# eusci_b register map
Vendor: Texas Instruments
Peripheral module from a debugger description file (folder MSP432).
Registers are 16-bit, read-write, no defined reset value unless marked. A register's access mark holds for its fields unless they carry their own. Offsets are as the file gives them; lines under a group give offsets from that group; [hi:lo] are bit positions; {n}, {i} and the like mark numbered series; 'fields as' and 'values as' point back to an identical list; <NAME> marks a mode.

## eUSCI_B
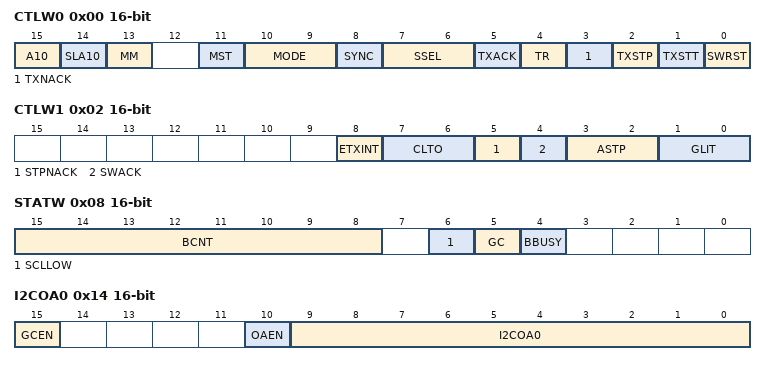
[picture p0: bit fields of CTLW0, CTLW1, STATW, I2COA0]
0x00 CTLW0 — eUSCI_Bx Control Word Register 0
  [15] A10 — Own addressing mode select. Modify only when UCSWRST = 1.
    0=A10__0 (Own address is a 7-bit address); 1=A10__1 (Own address is a 10-bit address)
  [14] SLA10 — Slave addressing mode select
    0=SLA10__0 (Address slave with 7-bit address); 1=SLA10__1 (Address slave with 10-bit address)
  [13] MM — Multi-master environment select. Modify only when UCSWRST = 1.
    0=MM__0 (Single master environment); 1=MM__1 (Multi-master environment)
  [11] MST — Master mode select
    0=MST__0 (Slave mode); 1=MST__1 (Master mode)
  [10:9] MODE — eUSCI_B mode
    0=MODE__0 (3-pin SPI); 1=MODE__1 (4-pin SPI (master or slave enabled if STE = 1)); 2=MODE__2 (4-pin SPI (master or slave enabled if STE = 0)); 3=MODE__3 (I2C mode)
  [8] SYNC — Synchronous mode enable. For eUSCI_B always read and write as 1.
    0=SYNC__0 (Asynchronous mode); 1=SYNC__1 (Synchronous mode)
  [7:6] SSEL — eUSCI_B clock source select
    0=SSEL__0 (UCLKI); 1=SSEL__1 (ACLK); 2=SSEL__2 (SMCLK); 3=SSEL__3 (SMCLK)
  [5] TXACK — Transmit ACK condition in slave mode with enabled address mask
    0=TXACK__0 (Do not acknowledge the slave address); 1=TXACK__1 (Acknowledge the slave address)
  [4] TR — Transmitter/receiver
    0=TR__0 (Receiver); 1=TR__1 (Transmitter)
  [3] TXNACK — Transmit a NACK
    0=TXNACK__0 (Acknowledge normally); 1=TXNACK__1 (Generate NACK)
  [2] TXSTP — Transmit STOP condition in master mode
    0=TXSTP__0 (No STOP generated); 1=TXSTP__1 (Generate STOP)
  [1] TXSTT — Transmit START condition in master mode
    0=TXSTT__0 (Do not generate START condition); 1=TXSTT__1 (Generate START condition)
  [0] SWRST — Software reset enable Modify only when UCSWRST = 1.
    0=SWRST__0 (Disabled. eUSCI_B reset released for operation); 1=SWRST__1 (Enabled. eUSCI_B logic held in reset state)
0x02 CTLW1 — eUSCI_Bx Control Word Register 1
  [8] ETXINT — Early UCTXIFG0
    0=ETXINT__0 (UCTXIFGx is set after an address match with UCxI2COAx and the d); 1=ETXINT__1 (UCTXIFG0 is set for each START condition)
  [7:6] CLTO — Clock low timeout select. Modify only when UCSWRST = 1.
    0=CLTO__0 (Disable clock low timeout counter); 1=CLTO__1 (135 000 SYSCLK cycles (approximately 28 ms)); 2=CLTO__2 (150 000 SYSCLK cycles (approximately 31 ms)); 3=CLTO__3 (165 000 SYSCLK cycles (approximately 34 ms))
  [5] STPNACK — The UCSTPNACK bit allows to make the eUSCI_B master acknowledge
    0=STPNACK__0 (Send a non-acknowledge before the STOP condition as a master re); 1=STPNACK__1 (All bytes are acknowledged by the eUSCI_B when configured as ma)
  [4] SWACK — Using this bit it is possible to select, whether the eUSCI_B mo
    0=SWACK__0 (The address acknowledge of the slave is controlled by the eUSCI); 1=SWACK__1 (The user needs to trigger the sending of the address ACK by iss)
  [3:2] ASTP — Automatic STOP condition generation
    0=ASTP__0 (No automatic STOP generation); 1=ASTP__1 (UCBCNTIFG is set with the byte counter reaches the threshold de); 2=ASTP__2 (A STOP condition is generated automatically after the byte coun)
  [1:0] GLIT — Deglitch time
    0=GLIT__0 (50 ns); 1=GLIT__1 (25 ns); 2=GLIT__2 (12.5 ns); 3=GLIT__3 (6.25 ns)
0x06 BRW — eUSCI_Bx Baud Rate Control Word Register
  [15:0] BR — Bit clock prescaler. Modify only when UCSWRST = 1.
0x08 STATW — eUSCI_Bx Status Register
  [15:8] BCNT — Hardware byte counter value
  [6] SCLLOW
    0=SCLLOW__0 (SCL is not held low); 1=SCLLOW__1 (SCL is held low)
  [5] GC — General call address received
    0=GC__0 (No general call address received); 1=GC__1 (General call address received)
  [4] BBUSY — Bus busy
    0=BBUSY__0 (Bus inactive); 1=BBUSY__1 (Bus busy)
0x0A TBCNT — eUSCI_Bx Byte Counter Threshold Register
  [7:0] TBCNT — The byte counter threshold value is used to set the number of I
0x0C RXBUF — eUSCI_Bx Receive Buffer Register
  [7:0] RXBUF — The receive-data buffer is user accessible and contains the las
0x0E TXBUF — eUSCI_Bx Transmit Buffer Register
  [7:0] TXBUF — The transmit data buffer is user accessible and holds the data
0x14 I2COA0 — eUSCI_Bx I2C Own Address 0 Register
  [15] GCEN — General call response enable
    0=GCEN__0 (Do not respond to a general call); 1=GCEN__1 (Respond to a general call)
  [10] OAEN — Own Address enable register
    0=OAEN__0 (The slave address defined in I2COA0 is disabled); 1=OAEN__1 (The slave address defined in I2COA0 is enabled)
  [9:0] I2COA0 — I2C own address
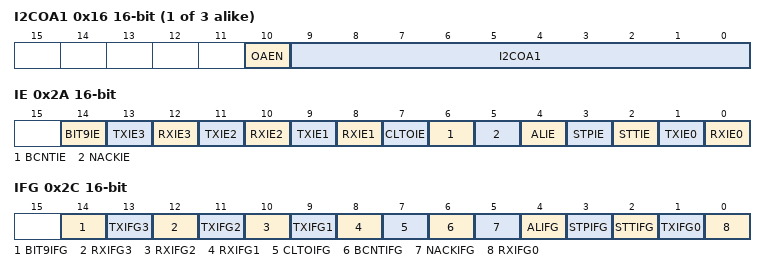
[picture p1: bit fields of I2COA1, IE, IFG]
{0x14+2i} I2COA{i} (i=1..3) — eUSCI_Bx I2C Own Address {i} Register
  [10] OAEN — Own Address enable register
    0=OAEN__0 (The slave address defined in I2COA{i} is disabled); 1=OAEN__1 (The slave address defined in I2COA{i} is enabled)
  [9:0] I2COA{i} — I2C own address
0x1C ADDRX — eUSCI_Bx I2C Received Address Register
  [9:0] ADDRX — Received Address Register
0x1E ADDMASK — eUSCI_Bx I2C Address Mask Register
  [9:0] ADDMASK — Address Mask Register
0x20 I2CSA — eUSCI_Bx I2C Slave Address Register
  [9:0] I2CSA — I2C slave address
0x2A IE — eUSCI_Bx Interrupt Enable Register
  [14] BIT9IE — Bit position 9 interrupt enable
    0=BIT9IE__0 (Interrupt disabled); 1=BIT9IE__1 (Interrupt enabled)
  [13] TXIE3 — Transmit interrupt enable 3
    0=TXIE3__0 (Interrupt disabled); 1=TXIE3__1 (Interrupt enabled)
  [12] RXIE3 — Receive interrupt enable 3
    0=RXIE3__0 (Interrupt disabled); 1=RXIE3__1 (Interrupt enabled)
  [11] TXIE2 — Transmit interrupt enable 2
    0=TXIE2__0 (Interrupt disabled); 1=TXIE2__1 (Interrupt enabled)
  [10] RXIE2 — Receive interrupt enable 2
    0=RXIE2__0 (Interrupt disabled); 1=RXIE2__1 (Interrupt enabled)
  [9] TXIE1 — Transmit interrupt enable 1
    0=TXIE1__0 (Interrupt disabled); 1=TXIE1__1 (Interrupt enabled)
  [8] RXIE1 — Receive interrupt enable 1
    0=RXIE1__0 (Interrupt disabled); 1=RXIE1__1 (Interrupt enabled)
  [7] CLTOIE — Clock low timeout interrupt enable
    0=CLTOIE__0 (Interrupt disabled); 1=CLTOIE__1 (Interrupt enabled)
  [6] BCNTIE — Byte counter interrupt enable
    0=BCNTIE__0 (Interrupt disabled); 1=BCNTIE__1 (Interrupt enabled)
  [5] NACKIE — Not-acknowledge interrupt enable
    0=NACKIE__0 (Interrupt disabled); 1=NACKIE__1 (Interrupt enabled)
  [4] ALIE — Arbitration lost interrupt enable
    0=ALIE__0 (Interrupt disabled); 1=ALIE__1 (Interrupt enabled)
  [3] STPIE — STOP condition interrupt enable
    0=STPIE__0 (Interrupt disabled); 1=STPIE__1 (Interrupt enabled)
  [2] STTIE — START condition interrupt enable
    0=STTIE__0 (Interrupt disabled); 1=STTIE__1 (Interrupt enabled)
  [1] TXIE0 — Transmit interrupt enable 0
    0=TXIE0__0 (Interrupt disabled); 1=TXIE0__1 (Interrupt enabled)
  [0] RXIE0 — Receive interrupt enable 0
    0=RXIE0__0 (Interrupt disabled); 1=RXIE0__1 (Interrupt enabled)
0x2C IFG — eUSCI_Bx Interrupt Flag Register
  [14] BIT9IFG — Bit position 9 interrupt flag
    0=BIT9IFG__0 (No interrupt pending); 1=BIT9IFG__1 (Interrupt pending)
  [13] TXIFG3 — eUSCI_B transmit interrupt flag 3
    0=TXIFG3__0 (No interrupt pending); 1=TXIFG3__1 (Interrupt pending)
  [12] RXIFG3 — eUSCI_B receive interrupt flag 3
    0=RXIFG3__0 (No interrupt pending); 1=RXIFG3__1 (Interrupt pending)
  [11] TXIFG2 — eUSCI_B transmit interrupt flag 2
    0=TXIFG2__0 (No interrupt pending); 1=TXIFG2__1 (Interrupt pending)
  [10] RXIFG2 — eUSCI_B receive interrupt flag 2
    0=RXIFG2__0 (No interrupt pending); 1=RXIFG2__1 (Interrupt pending)
  [9] TXIFG1 — eUSCI_B transmit interrupt flag 1
    0=TXIFG1__0 (No interrupt pending); 1=TXIFG1__1 (Interrupt pending)
  [8] RXIFG1 — eUSCI_B receive interrupt flag 1
    0=RXIFG1__0 (No interrupt pending); 1=RXIFG1__1 (Interrupt pending)
  [7] CLTOIFG — Clock low timeout interrupt flag
    0=CLTOIFG__0 (No interrupt pending); 1=CLTOIFG__1 (Interrupt pending)
  [6] BCNTIFG — Byte counter interrupt flag
    0=BCNTIFG__0 (No interrupt pending); 1=BCNTIFG__1 (Interrupt pending)
  [5] NACKIFG — Not-acknowledge received interrupt flag
    0=NACKIFG__0 (No interrupt pending); 1=NACKIFG__1 (Interrupt pending)
  [4] ALIFG — Arbitration lost interrupt flag
    0=ALIFG__0 (No interrupt pending); 1=ALIFG__1 (Interrupt pending)
  [3] STPIFG — STOP condition interrupt flag
    0=STPIFG__0 (No interrupt pending); 1=STPIFG__1 (Interrupt pending)
  [2] STTIFG — START condition interrupt flag
    0=STTIFG__0 (No interrupt pending); 1=STTIFG__1 (Interrupt pending)
  [1] TXIFG0 — eUSCI_B transmit interrupt flag 0
    0=TXIFG0__0 (No interrupt pending); 1=TXIFG0__1 (Interrupt pending)
  [0] RXIFG0 — eUSCI_B receive interrupt flag 0
    0=RXIFG0__0 (No interrupt pending); 1=RXIFG0__1 (Interrupt pending)
0x2E IV — eUSCI_Bx Interrupt Vector Register
  [15:0] IV — eUSCI_B interrupt vector value
    0=IV__0 (No interrupt pending); 2=IV__2 (Interrupt Source: Arbitration lost; Interrupt Flag: UCALIFG; In); 4=IV__4 (Interrupt Source: Not acknowledgment; Interrupt Flag: UCNACKIFG); 6=IV__6 (Interrupt Source: Start condition received; Interrupt Flag: UCS); 8=IV__8 (Interrupt Source: Stop condition received; Interrupt Flag: UCST); 10=IV__16 (Interrupt Source: Slave 3 Data received; Interrupt Flag: UCRXIF); 12=IV__18 (Interrupt Source: Slave 3 Transmit buffer empty; Interrupt Flag); 14=IV__20 (Interrupt Source: Slave 2 Data received; Interrupt Flag: UCRXIF); 16=IV__22 (Interrupt Source: Slave 2 Transmit buffer empty; Interrupt Flag); 18=IV__24 (Interrupt Source: Slave 1 Data received; Interrupt Flag: UCRXIF); 20=IV__32 (Interrupt Source: Slave 1 Transmit buffer empty; Interrupt Flag); 22=IV__34 (Interrupt Source: Data received; Interrupt Flag: UCRXIFG0); 24=IV__36 (Interrupt Source: Transmit buffer empty; Interrupt Flag: UCTXIF); 26=IV__38 (Interrupt Source: Byte counter zero; Interrupt Flag: UCBCNTIFG); 28=IV__40 (Interrupt Source: Clock low timeout; Interrupt Flag: UCCLTOIFG); 30=IV__48 (Interrupt Source: Nineth bit position; Interrupt Flag: UCBIT9IF)
